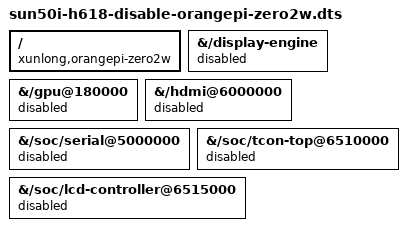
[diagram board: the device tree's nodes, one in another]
/dts-v1/;
/plugin/;
/ {
        compatible = "xunlong,orangepi-zero2w\0allwinner,sun50i-h618";

        fragment@0 {
		target-path = "/display-engine";
		__overlay__ {
		status = "disabled";
			};
		};

	fragment@1 {
		target-path = "/gpu@180000";
		__overlay__ {
		status = "disabled";
			};
		};

	fragment@2 {
		target-path = "/hdmi@6000000";
		__overlay__ {
		status = "disabled";
			};
		};

	fragment@3 {
		target-path  = "/soc/serial@5000000";
		__overlay__ {
		status = "disabled";
			};
		};

        fragment@4 {
                target-path = "/soc/tcon-top@6510000";
                __overlay__ {
                status = "disabled";
                        };
                };

	fragment@5 {
		target-path = "/soc/lcd-controller@6515000";
		__overlay__ {
		status = "disabled";
			};
		};
	};
